# RS1xxxx register map
Vendor: Silicon Lab Inc.; Series: ARMCM4; File version: 1.2
CPU: CM4 r1p0, little endian, MPU, FPU, 6 interrupt priority bits
Registers are 32-bit, read-write, reset 0x0 unless marked. A register's access mark holds for its fields unless they carry their own. Offsets are from the block's base; [hi:lo] are bit positions; 'fields as' and 'values as' point back to an identical list.

## I2C0 — Inter Integrated Circuit(I2C) is programmable control bus that provides support for the communications link between integrated circuits in a system
Base 0x44010000
Same registers: ULP_I2C 0x24040000, I2C1 0x47040000
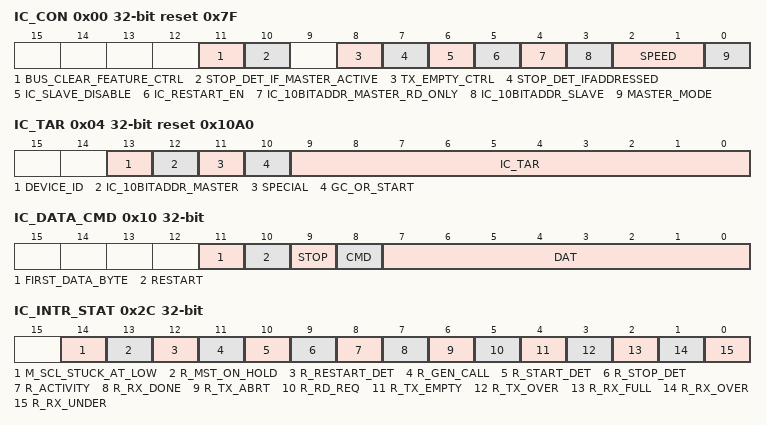
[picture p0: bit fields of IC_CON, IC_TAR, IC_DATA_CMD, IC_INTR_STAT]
0x00 IC_CON reset 0x7F — This register can be written only when the i2c is disabled, which corresponds to IC_ENABLE[0] being set to 0. Writes at other times have no effect.
  [11] BUS_CLEAR_FEATURE_CTRL — In Master mode.
    0=Disable (Bus Clear Feature is disabled); 1=Enable (Bus Clear Feature is enabled)
  [10] STOP_DET_IF_MASTER_ACTIVE — In Master mode.
    0=Disable (Issues the STOP_DET irrespective of whether the master is active.); 1=Enable (Issues the STOP_DET interrupt only when the master is active)
  [8] TX_EMPTY_CTRL — This bit controls the generation of the TX EMPTY interrupt, as described in the IC RAW INTR STAT register.
  [7] STOP_DET_IFADDRESSED — The STOP DETECTION interrupt is generated only when the transmitted address matches the slave address of SAR
    0=Disable (Issues the STOP DETECTION irrespective of whether it is addressed or not.); 1=Enable (issues the STOP DETECTION interrupt only when it is addressed.)
  [6] IC_SLAVE_DISABLE — This bit controls whether I2C has its slave disabled
    0=Disable (slave is enabled); 1=Enable (slave is disabled)
  [5] IC_RESTART_EN — Determines whether RESTART conditions may be sent when acting as a master
    0=Disabled; 1=Enabled
  [4] IC_10BITADDR_MASTER_RD_ONLY ro — the function of this bit is handled by bit 12 of IC_TAR register, and becomes a read-only copy called IC_10BITADDR_MASTER_rd_only
    0=Disable (7-bit addressing); 1=Enable (10-bit addressing)
  [3] IC_10BITADDR_SLAVE — When acting as a slave, this bit controls whether the I2C responds to 7- or 10-bit addresses.
    0=Disable (7-bit addressing. The DW_apb_i2c ignores transactions that involve 10-bit addressing; for 7-bit addressing, only the lower 7 bits of the IC_SAR register are compared); 1=Enable (10-bit addressing. The DW_apb_i2c responds to only 10-bit addressing transfers that match the full 10 bits of the IC_SAR register.)
  [2:1] SPEED — These bits control at which speed the I2C operates. Hardware protects against illegal values being programmed by software.
    1=standard mode (0 to 100 kbit/s); 2=fast mode (less than or equal 400 kbit/s); 3=high speed mode (less than or equal 3.4 Mbit/s)
  [0] MASTER_MODE — This bit controls whether the I2C master is enabled.
    0=Disable (master disabled); 1=Enable (master enabled)
0x04 IC_TAR reset 0x10A0 — I2C Target Address Register
  [13] DEVICE_ID — If bit 11 (SPECIAL) is set to 1, then this bit indicates whether a Device-ID of a particular slave mentioned in IC_TAR[6:0] is to be performed by the I2C Master
    0=Disable (Device-ID is not performed and checks ic_tar[10] to perform either general call or START byte command.); 1=Enable (: Device-ID transfer is performed and bytes based on the number of read commands in the Tx-FIFO are received from the targeted slave and put in the Rx-FIFO.)
  [12] IC_10BITADDR_MASTER — This bit controls whether the i2c starts its transfers in 7-or 10-bit addressing mode when acting as a master
    0=Disable (7-bit addressing); 1=Enable (10-bit addressing)
  [11] SPECIAL — This bit indicates whether software performs a General Call or START BYTE command
    0=Disable (ignore bit 10 GC_OR_START and use IC_TAR normally); 1=Enable (perform special I2C command as specified in GC_OR_START bit)
  [10] GC_OR_START — If bit 11 (SPECIAL) is set to 1, then this bit indicates whether a General Call or START byte command is to be performed by the DW_apb_i2c
    0=Disable (General Call Address); 1=Enable (START BYTE)
  [9:0] IC_TAR — This is the target address for any master transaction
0x08 IC_SAR reset 0x55 — I2C Slave Address Register
  [9:0] IC_SAR — The IC_SAR holds the slave address when the I2C is operating as a slave. For 7-bit addressing, only IC_SAR[6:0] is used.
0x0C IC_HS_MADDR reset 0x1 — I2C High Speed Master Mode Code Address Register
  [2:0] IC_HS_MAR — This bit field holds the value of the I2C HS mode master code
0x10 IC_DATA_CMD — I2C Rx/Tx Data Buffer and Command Register
  [11] FIRST_DATA_BYTE ro — Indicates the first data byte received after the address phase for receive transfer in Master receiver or Slave receiver mode
    0=Disable (If IC_RESTART_EN is 1, a RESTART is issued only if the transfer direction is changing from the previous command); 1=Enable (If IC_RESTART_EN is 1, a RESTART is issued before the data is sent/received)
  [10] RESTART wo — This bit controls whether a RESTART is issued before the byte is sent or received
    values as FIRST_DATA_BYTE
  [9] STOP wo — This bit controls whether a STOP is issued after the byte is sent or received
    0=Disable (STOP is not issued after this byte, regardless of whether or not the Tx FIFO is empty); 1=Enable (STOP is issued after this byte, regardless of whether or not the Tx FIFO is empty)
  [8] CMD wo — This bit controls whether a read or a write is performed
    0=Disable (write); 1=Enable (Read)
  [7:0] DAT — This register contains the data to be transmitted or received on the I2C bus
0x14 IC_SS_SCL_HCNT reset 0x1F4 — Standard Speed I2C Clock SCL High Count Register
  [15:0] IC_SS_SCL_HCNT — This register must be set before any I2C bus transaction can take place to ensure proper I/O timing
0x18 IC_SS_SCL_LCNT reset 0x24C — Standard Speed I2C Clock SCL Low Count Register
  [15:0] IC_SS_SCL_LCNT — This register must be set before any I2C bus transaction can take place to ensure proper I/O timing
0x1C IC_FS_SCL_HCNT reset 0x4B — Fast Speed I2C Clock SCL High Count Register
  [15:0] IC_FS_SCL_HCNT — This register must be set before any I2C bus transaction can take place to ensure proper I/O timing
0x20 IC_FS_SCL_LCNT reset 0xA3 — Fast Speed I2C Clock SCL Low Count Register
  [15:0] IC_FS_SCL_LCNT — This register must be set before any I2C bus transaction can take place to ensure proper I/O timing
0x24 IC_HS_SCL_HCNT reset 0xF — High Speed I2C Clock SCL High Count Register
  [15:0] IC_HS_SCL_HCNT — This register must be set before any I2C bus transaction can take place to ensure proper I/O timing
0x28 IC_HS_SCL_LCNT reset 0x28 — High Speed I2C Clock SCL Low Count Register
  [15:0] IC_HS_SCL_LCNT — This register must be set before any I2C bus transaction can take place to ensure proper I/O timing
0x2C IC_INTR_STAT ro — I2C Interrupt Status Register
  [14] M_SCL_STUCK_AT_LOW — Indicates whether the SCL Line is stuck at low for the IC_SCL_STUCK_LOW_TIMOUT number of ic_clk periods
  [13] R_MST_ON_HOLD — Indicates whether a master is holding the bus and the Tx FIFO is empty.
  [12] R_RESTART_DET — Indicates whether a RESTART condition has occurred on the I2C interface when DW_apb_i2c is operating in slave mode and the slave is the addressed slave
  [11] R_GEN_CALL — Set only when a General Call address is received and it is acknowledged
  [10] R_START_DET — Indicates whether a START or RESTART condition has occurred on the I2C interface regardless of whether DW_apb_i2c is operating in slave or master mode.
  [9] R_STOP_DET — Indicates whether a STOP condition has occurred on the I2C interface regardless of whether DW_apb_i2c is operating in slave or master mode.
  [8] R_ACTIVITY — This bit captures DW_apb_i2c activity and stays set until it is cleared
  [7] R_RX_DONE — When the DW_apb_i2c is acting as a slave-transmitter, this bit is set to 1 if the master does not acknowledge a transmitted byte
  [6] R_TX_ABRT — This bit indicates if DW_apb_i2c, as an I2C transmitter, is unable to complete the intended actions on the contents of the transmit FIFO
  [5] R_RD_REQ — This bit is set to 1 when DW_apb_i2c is acting as a slave and another I2C master is attempting to read data from DW_apb_i2c.
  [4] R_TX_EMPTY — This bit is set to 1 when the transmit buffer is at or below the threshold value set in the IC_TX_TL register.
  [3] R_TX_OVER — Set during transmit if the transmit buffer is filled to IC_TX_BUFFER_DEPTH and the processor attempts to issue another I2C command by writing to the IC_DATA_CMD register.
  [2] R_RX_FULL — Set when the receive buffer reaches or goes above the RX_TL threshold in the IC_RX_TL register.
  [1] R_RX_OVER — Set if the receive buffer is completely filled to IC_RX_BUFFER_DEPTH and an additional byte is received from an external I2C device
  [0] R_RX_UNDER — Set if the processor attempts to read the receive buffer when it is empty by reading from the IC_DATA_CMD register
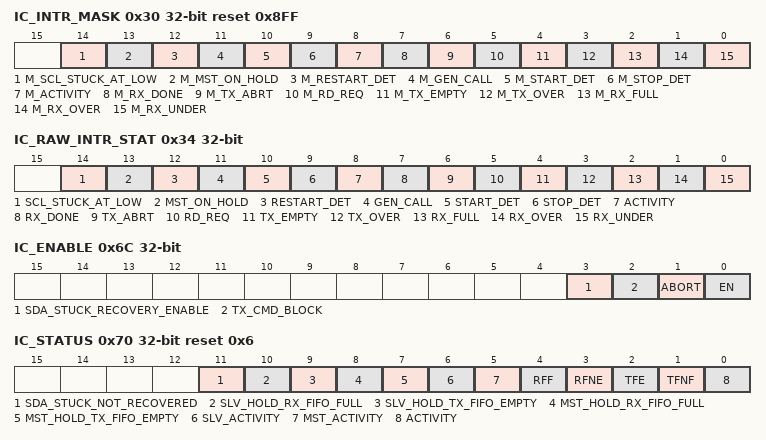
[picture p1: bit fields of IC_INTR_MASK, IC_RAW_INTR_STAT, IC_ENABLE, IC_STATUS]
0x30 IC_INTR_MASK reset 0x8FF — I2C Interrupt Mask Register
  [14] M_SCL_STUCK_AT_LOW — Indicates whether the SCL Line is stuck at low for the IC_SCL_STUCK_LOW_TIMOUT number of ic_clk periods
  [13] M_MST_ON_HOLD — Indicates whether a master is holding the bus and the Tx FIFO is empty.
  [12] M_RESTART_DET — Indicates whether a RESTART condition has occurred on the I2C interface when DW_apb_i2c is operating in slave mode and the slave is the addressed slave
  [11] M_GEN_CALL — This bit mask their corresponding interrupt status bits in the IC_INTR_STAT register.
  [10] M_START_DET — This bit mask their corresponding interrupt status bits in the IC_INTR_STAT register.
  [9] M_STOP_DET — This bit mask their corresponding interrupt status bits in the IC_INTR_STAT register.
  [8] M_ACTIVITY — This bit mask their corresponding interrupt status bits in the IC_INTR_STAT register.
  [7] M_RX_DONE — This bit mask their corresponding interrupt status bits in the IC_INTR_STAT register.
  [6] M_TX_ABRT — This bit mask their corresponding interrupt status bits in the IC_INTR_STAT register.
  [5] M_RD_REQ — This bit mask their corresponding interrupt status bits in the IC_INTR_STAT register.
  [4] M_TX_EMPTY — This bit mask their corresponding interrupt status bits in the IC_INTR_STAT register.
  [3] M_TX_OVER — This bit mask their corresponding interrupt status bits in the IC_INTR_STAT register
  [2] M_RX_FULL — This bit mask their corresponding interrupt status bits in the IC_INTR_STAT register.
  [1] M_RX_OVER — This bit mask their corresponding interrupt status bits in the IC_INTR_STAT register.
  [0] M_RX_UNDER — This bit mask their corresponding interrupt status bits in the IC_INTR_STAT register.
0x34 IC_RAW_INTR_STAT ro — I2C Raw Interrupt Status Register
  [14] SCL_STUCK_AT_LOW — Indicates whether the SCL Line is stuck at low for the IC_SCL_STUCK_LOW_TIMOUT number of ic_clk periods
  [13] MST_ON_HOLD — Indicates whether a master is holding the bus and the Tx FIFO is empty.
  [12] RESTART_DET — Indicates whether a RESTART condition has occurred on the I2C interface when DW_apb_i2c is operating in slave mode and the slave is the addressed slave
  [11] GEN_CALL — Set only when a General Call address is received and it is acknowledged
  [10] START_DET — Indicates whether a START or RESTART condition has occurred on the I2C interface regardless of whether DW_apb_i2c is operating in slave or master mode.
  [9] STOP_DET — Indicates whether a STOP condition has occurred on the I2C interface regardless of whether DW_apb_i2c is operating in slave or master mode.
  [8] ACTIVITY — This bit captures DW_apb_i2c activity and stays set until it is cleared
  [7] RX_DONE — When the DW_apb_i2c is acting as a slave-transmitter, this bit is set to 1 if the master does not acknowledge a transmitted byte
  [6] TX_ABRT — This bit indicates if DW_apb_i2c, as an I2C transmitter, is unable to complete the intended actions on the contents of the transmit FIFO
  [5] RD_REQ — This bit is set to 1 when DW_apb_i2c is acting as a slave and another I2C master is attempting to read data from DW_apb_i2c.
  [4] TX_EMPTY — This bit is set to 1 when the transmit buffer is at or below the threshold value set in the IC_TX_TL register.
  [3] TX_OVER — Set during transmit if the transmit buffer is filled to IC_TX_BUFFER_DEPTH and the processor attempts to issue another I2C command by writing to the IC_DATA_CMD register.
  [2] RX_FULL — Set when the receive buffer reaches or goes above the RX_TL threshold in the IC_RX_TL register.
  [1] RX_OVER — Set if the receive buffer is completely filled to IC_RX_BUFFER_DEPTH and an additional byte is received from an external I2C device
  [0] RX_UNDER — Set if the processor attempts to read the receive buffer when it is empty by reading from the IC_DATA_CMD register
0x38 IC_RX_TL reset 0x8 — I2C Receive FIFO Threshold Register
  [7:0] RX_TL — Receive FIFO Threshold Level
0x3C IC_TX_TL reset 0x8 — I2C Transmit FIFO Threshold Register
  [7:0] TX_TL — Transmit FIFO Threshold Level
0x40 IC_CLR_INTR ro — Clear Combined and Individual Interrupt Register
  [0] CLR_INTR — Read this register to clear the combined interrupt, all individual interrupts, and the IC_TXABRT_SOURCE register
0x44 IC_CLR_RX_UNDER ro — Clear RX_UNDER Interrupt Register
  [0] CLR_RX_UNDER — Read this register to clear the RX_UNDER interrupt (bit 0) of the IC_RAW_INTR_STAT register.
0x48 IC_CLR_RX_OVER ro — Clear RX_OVER Interrupt Register
  [0] CLR_RX_OVER — Read this register to clear the RX_OVER interrupt (bit 1) of the IC_RAW_INTR_STAT register
0x4C IC_CLR_TX_OVER ro — Clear TX_OVER Interrupt Register
  [0] CLR_TX_OVER — Read this register to clear the TX_OVER interrupt (bit 3) of the IC_RAW_INTR_STAT register.
0x50 IC_CLR_RD_REQ ro — Clear RD_REQ Interrupt Register
  [0] CLR_RD_REQ — Read this register to clear the RD_REQ interrupt (bit 5) of the IC_RAW_INTR_STAT register.
0x54 IC_CLR_TX_ABRT ro — Clear TX_ABRT Interrupt Register
  [0] CLR_TX_ABRT — Read this register to clear the TX_ABRT interrupt (bit 6) of the C_RAW_INTR_STAT register, and the IC_TX_ABRT_SOURCE register
0x58 IC_CLR_RX_DONE ro — Clear RX_DONE Interrupt Register
  [0] CLR_RX_DONE — Read this register to clear the RX_DONE interrupt (bit 7) of the IC_RAW_INTR_STAT register
0x5C IC_CLR_ACTIVITY ro — Clear ACTIVITY Interrupt Register
  [0] CLR_ACTIVITY — Reading this register clears the ACTIVITY interrupt if the I2C is not active any more
0x60 IC_CLR_STOP_DET ro — Clear STOP_DET Interrupt Register
  [0] CLR_STOP_DET — Read this register to clear the STOP_DET interrupt (bit 9) of the IC_RAW_INTR_STAT register.
0x64 IC_CLR_START_DET ro — Clear START_DET Interrupt Register
  [0] CLR_START_DET — Read this register to clear the START_DET interrupt (bit 10) of the IC_RAW_INTR_STAT register
0x68 IC_CLR_GEN_CALL ro — Clear GEN_CALL Interrupt Register
  [0] CLR_GEN_CALL — Read this register to clear the GEN_CALL interrupt (bit 11) of IC_RAW_INTR_STAT register
0x6C IC_ENABLE (reset mask 0x1) — Clear GEN_CALL Interrupt Register
  [3] SDA_STUCK_RECOVERY_ENABLE
  [2] TX_CMD_BLOCK
    0=Disable (The transmission of data starts on I2C bus automatically, as soon as the first data is available in the Tx FIFO); 1=Enable (Blocks the transmission of data on I2C bus even if Tx FIFO has data to transmit)
  [1] ABORT — When set, the controller initiates the transfer abort
    0=Disable (ABORT not initiated or ABORT done); 1=Enable (ABORT operation in progress)
  [0] EN — Controls whether the DW_apb_i2c is enabled
    0=Disables DW_apb_i2c (TX and RX FIFOs are held in an erased state); 1=Enables DW_apb_i2c
0x70 IC_STATUS ro reset 0x6 (reset mask 0xF) — I2C Status Register
  [11] SDA_STUCK_NOT_RECOVERED — This bit indicates that an SDA stuck at low is not recovered after the recovery mechanism.
  [10] SLV_HOLD_RX_FIFO_FULL — This bit indicates the BUS Hold in Slave mode due to the Rx FIFO being Full and an additional byte being received.
  [9] SLV_HOLD_TX_FIFO_EMPTY — This bit indicates the BUS Hold in Slave mode for the Read request when the Tx FIFO is empty.
  [8] MST_HOLD_RX_FIFO_FULL — This bit indicates the BUS Hold in Master mode due to Rx FIFO is Full and additional byte has been received.
  [7] MST_HOLD_TX_FIFO_EMPTY — The I2C master stalls the write transfer when Tx FIFO is empty, and the the last byte does not have the Stop bit set.
  [6] SLV_ACTIVITY — Slave FSM Activity Status
    0=Disable (Slave FSM is in IDLE state so the Slave part of DW_apb_i2c is not Active); 1=Enable (Slave FSM is not in IDLE state so the Slave part of DW_apb_i2c is Active)
  [5] MST_ACTIVITY — Master FSM Activity Status
    0=Disable (Master FSM is in IDLE state so the Master part of DW_apb_i2c is not Active); 1=Enable (Master FSM is not in IDLE state so the Master part of DW_apb_i2c is Active)
  [4] RFF — Receive FIFO Completely Full
    0=Disable (Receive FIFO is not full); 1=Enable (Receive FIFO is full)
  [3] RFNE — Receive FIFO Not Empty
    0=Disable (Receive FIFO is not empty); 1=Enable (Receive FIFO is not empty)
  [2] TFE — Transmit FIFO Completely Empty
    0=Disable (Transmit FIFO is not empty); 1=Enable (Transmit FIFO is empty)
  [1] TFNF — Transmit FIFO Not Full
    0=Disable (Transmit FIFO is full); 1=Enable (Transmit FIFO is not full)
  [0] ACTIVITY — I2C Activity Status
0x74 IC_TXFLR ro — I2C Transmit FIFO Level Register
  [3:0] TXFLR — Contains the number of valid data entries in the transmit FIFO.
0x78 IC_RXFLR ro — I2C Receive FIFO Level Register
  [3:0] RXFLR — Receive FIFO Level. Contains the number of valid data entries in the receive FIFO
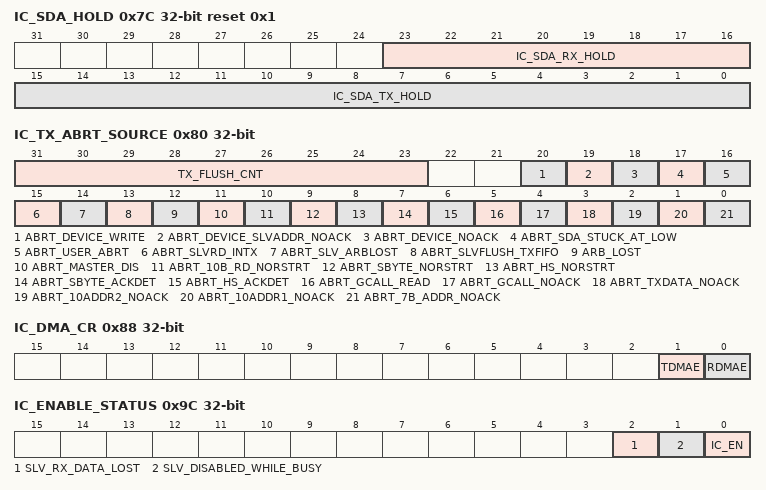
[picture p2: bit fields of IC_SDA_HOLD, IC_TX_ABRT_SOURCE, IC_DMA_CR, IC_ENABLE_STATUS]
0x7C IC_SDA_HOLD reset 0x1 (reset mask 0xF) — I2C SDA Hold Time Length Register
  [23:16] IC_SDA_RX_HOLD — Sets the required SDA hold time in units of ic_clk period,when I2C acts as a receiver.
  [15:0] IC_SDA_TX_HOLD — Sets the required SDA hold time in units of ic_clk period,when I2C acts as a transmitter.
0x80 IC_TX_ABRT_SOURCE ro (reset mask 0xFFFF) — I2C Transmit Abort Source Register
  [31:23] TX_FLUSH_CNT — This field indicates the number of Tx FIFO data commands that are flushed due to TX_ABRT interrupt
  [20] ABRT_DEVICE_WRITE — Master is initiating the DEVICE_ID transfer and the Tx- FIFO consists of write commands.
  [19] ABRT_DEVICE_SLVADDR_NOACK — Master is initiating the DEVICE_ID transfer and the slave address sent was not acknowledged by any slave
  [18] ABRT_DEVICE_NOACK — Master initiates the DEVICE_ID transfer and the device ID sent is not acknowledged by any slave
  [17] ABRT_SDA_STUCK_AT_LOW — Master detects the SDA is Stuck at low for the IC_SDA_STUCK_AT_LOW_TIMEOUT value of ic_clks
  [16] ABRT_USER_ABRT — This is a master-mode-only bit. Master has detected the transfer abort (IC_ENABLE[1]).
  [15] ABRT_SLVRD_INTX — 1: When the processor side responds to a slave mode request for data to be transmitted to a remote master and user writes a 1 in CMD (bit 8) of IC_DATA_CMD register
  [14] ABRT_SLV_ARBLOST — 1: Slave lost the bus while transmitting data to a remote master. IC_TX_ABRT_SOURCE[12] is set at the same time
  [13] ABRT_SLVFLUSH_TXFIFO — 1: Slave has received a read command and some data exists in the TX FIFO so the slave issues a TX_ABRT interrupt to flush old data in TX FIFO
  [12] ARB_LOST — 1: Master has lost arbitration, or if IC_TX_ABRT_SOURCE[14] is also set, then the slave transmitter has lost arbitration
  [11] ABRT_MASTER_DIS — 1: User tries to initiate a Master operation with the Master mode disabled
  [10] ABRT_10B_RD_NORSTRT — 1: The restart is disabled (IC_RESTART_EN bit (IC_CON[5]) = 0) and the master sends a read command in 10-bit addressing mode
  [9] ABRT_SBYTE_NORSTRT — 1: The restart is disabled (IC_RESTART_EN bit (IC_CON[5]) = 0) and the user is trying to send a START Byte
  [8] ABRT_HS_NORSTRT — 1: The restart is disabled (IC_RESTART_EN bit (IC_CON[5]) = 0) and the user is trying to use the master to transfer data in High Speed mode
  [7] ABRT_SBYTE_ACKDET — 1: Master has sent a START Byte and the START Byte was acknowledged (wrong behavior)
  [6] ABRT_HS_ACKDET — 1: Master is in High Speed mode and the High Speed Master code was acknowledged
  [5] ABRT_GCALL_READ — 1: DW_apb_i2c in master mode sent a General Call but the user programmed the byte following the General Call to be a read from the bus (IC_DATA_CMD[9] is set to 1)
  [4] ABRT_GCALL_NOACK — 1: DW_apb_i2c in master mode sent a General Call and no slave on the bus acknowledged the General Call
  [3] ABRT_TXDATA_NOACK — 1: This is a master-mode only bit. Master has received an acknowledgement for the address, but when it sent data byte(s) following the address, it did not receive an acknowledge from the remote slave(s)
  [2] ABRT_10ADDR2_NOACK — 1: Master is in 10-bit address mode and the second address byte of the 10-bit address was not acknowledged by any slave
  [1] ABRT_10ADDR1_NOACK — 1: Master is in 10-bit address mode and the first 10-bit address byte was not acknowledged by any slave
  [0] ABRT_7B_ADDR_NOACK — 1: Master is in 7-bit addressing mode and the address sent was not acknowledged by any slave
0x84 IC_SLV_DATA_NACK_ONLY — Generate Slave Data NACK Register
  [0] NACK — Generate NACK. This NACK generation only occurs when DW_apb_i2c is a slave receiver.
0x88 IC_DMA_CR — DMA Control Register
  [1] TDMAE — Transmit DMA Enable.This bit enables/disables the transmit FIFO DMA channel
    0=Disable (Transmit DMA disabled); 1=Enable (Transmit DMA enabled)
  [0] RDMAE — Receive DMA Enable
    0=Disable (Receive DMA disabled); 1=Enable (Receive DMA enabled)
0x8C IC_DMA_TDLR — DMA Transmit Data Level Register
  [3:0] DMATDL — This bit field controls the level at which a DMA request is made by the transmit logic
0x90 IC_DMA_RDLR (reset mask 0x7) — I2C Receive Data Level Register
  [3:0] DMARDL — This bit field controls the level at which a DMA request is made by the receive logic
0x94 IC_SDA_SETUP — I2C SDA Setup Register
  [7:0] SDA_SETUP — This register controls the amount of time delay (in terms of number of ic_clk clock periods)
0x98 IC_ACK_GENERAL_CALL reset 0x1 — I2C ACK General Call Register
  [0] ACK_GEN_CALL — ACK General Call
    0=Disable (DW_apb_i2c does not generate General Call interrupts); 1=Enable (DW_apb_i2c responds with a ACK (by asserting ic_data_oe) when it receives a General Call.)
0x9C IC_ENABLE_STATUS ro — I2C Enable Status Register
  [2] SLV_RX_DATA_LOST — Slave Received Data Lost
    0=Disable (DW_apb_i2c is deemed to have been actively engaged in an aborted I2C transfer (with matching address) and the data phase of the I2C transfer has been entered, even though a data byte has been responded with a NACK); 1=Enable (DW_apb_i2c is deemed to have been disabled without being actively involved in the data phase of a Slave-Receiver transfer)
  [1] SLV_DISABLED_WHILE_BUSY — This bit indicates if a potential or active Slave operation has been aborted due to the setting of the IC_ENABLE register from 1 to 0
    0=Disable (DW_apb_i2c is deemed to have been disabled when there is master activity, or when the I2C bus is idle.); 1=Enable (DW_apb_i2c is deemed to have forced a NACK during any part of an I2C transfer)
  [0] IC_EN — This bit always reflects the value driven on the output port ic_en.
    0=Disable (DW_apb_i2c is deemed completely inactive); 1=Enable (DW_apb_i2c is deemed to be in an enabled state)
0xA0 IC_FS_SPKLEN reset 0x6 (alternate view of IC_UFM_SPKLEN) — I2C SS and FS Spike Suppression Limit Register
  [7:0] IC_FS_SPKLEN — This register sets the duration, measured in ic_clk cycles, of the longest spike in the SCL or SDA lines that are filtered out by the spike suppression logic
0xA4 IC_HS_SPKLEN reset 0x2 — I2C HS Spike Suppression Limit Register
  [7:0] IC_HS_SPKLEN — This register sets the duration, measured in ic_clk cycles, of the longest spike in the SCL or SDA lines that are filtered out by the spike suppression logic
0xA8 IC_CLR_RESTART_DET ro — Clear RESTART_DET Interrupt Register
  [0] CLR_RESTART_DET — Read this register to clear the RESTART_DET interrupt (bit 12) of the IC_RAW_INTR_STAT registe
0xAC IC_SCL_STUCK_AT_LOW_TIMEOUT reset 0xFFFFFFFF — I2C SCL Stuck at Low Timeout
  [31:0] IC_SCL_STUCK_LOW_TIMEOUT — Generates the interrupt to indicate SCL stuck at low if it detects the SCL stuck at low for the IC_SCL_STUCK_LOW_TIMEOUT in units of ic_clk period
0xB0 IC_SDA_STUCK_AT_LOW_TIMEOUT reset 0xFFFFFFFF — I2C SDA Stuck at Low Timeout
  [31:0] IC_SDA_STUCK_LOW_TIMEOUT — Initiates the recovery of SDA line , if it detects the SDA stuck at low for the IC_SDA_STUCK_LOW_TIMEOUT in units of ic_clk period.
0xB4 IC_CLR_SCL_STUCK_DET ro — Clear SCL Stuck at Low Detect Interrupt Register
  [0] CLR_SCL_STUCK — Read this register to clear the SCL_STUCK_DET interrupt
0xB8 IC_DEVICE_ID ro reset 0x1 — I2C Device ID
  [0] DEVICE_ID — Contains the Device-ID of the component assigned through the configuration parameter
0xBC IC_SMBUS_CLOCK_LOW_SEXT reset 0xFFFFFFFF — SMBUS Slave Clock Extend Timeout Register
  [31:0] SMBUS_CLK_LOW_SEXT_TIMEOUT — The values in this register are in units of ic_clk period.
0xC0 IC_SMBUS_CLOCK_LOW_MEXT reset 0xFFFFFFFF — SMBUS Master extend clock Timeout Register
  [31:0] SMBUS_CLK_LOW_MEXT_TIMEOUT — The values in this register are in units of ic_clk period..
0xC4 IC_SMBUS_THIGH_MAX_IDLE_COUNT reset 0xFFFF — SMBus Thigh MAX Bus-Idle count Register
  [15:0] SMBUS_THIGH_MAX_BUS_IDLE_CNT — The values in this register are in units of ic_clk period.
0xC8 IC_SMBUS_INTR_STAT reset not defined — SMBUS Interrupt Status Register
0xCC IC_SMBUS_INTR_MASK reset not defined — Interrupt Mask Register
0xD0 IC_SMBUS_INTR_RAW_STATUS reset not defined — SMBUS Raw Interrupt Status Register
0xD4 IC_CLR_SMBUS_INTR reset not defined — Clear SMBUS Interrupt Register
0xD8 IC_OPTIONAL_SAR reset not defined — Optional Slave Address Register
0xDC IC_SMBUS_UDID_LSB reset 0xFFFFFFFF — SMBUS ARP UDID LSB Register
  [31:0] IC_SMBUS_ARP_UDID_LSB — This field is used to store the LSB 32 bit value of slave unique device identifier used in Address Resolution Protocol.
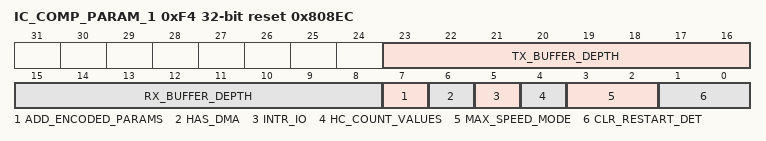
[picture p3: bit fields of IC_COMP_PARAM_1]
0xF4 IC_COMP_PARAM_1 ro reset 0x808EC — I2C HS Spike Suppression Limit Register
  [23:16] TX_BUFFER_DEPTH — Depth of Transmit buffer;the buffer is 8 bits wide;2 to 256
  [15:8] RX_BUFFER_DEPTH — Depth of receive buffer;the buffer is 8 bits wide;2 to 256
  [7] ADD_ENCODED_PARAMS — Add Encoded Parameters
  [6] HAS_DMA — DMA Handshake Interface signal
  [5] INTR_IO — Single Interrupt Output port
  [4] HC_COUNT_VALUES — Hard Code the count values
  [3:2] MAX_SPEED_MODE — Maximum Speed Mode
  [1:0] CLR_RESTART_DET — Read this register to clear the RESTART_DET interrupt (bit 12) of the IC_RAW_INTR_STAT register
0xF8 IC_COMP_VERSION ro — I2C Component Version Register
  [31:0] IC_COMP_VERSION — Signifies the component version
0xFC IC_COMP_TYPE ro — I2C Component Type Register
  [31:0] IC_COMP_TYPE — Design ware Component Type number = 0x44_57_01_40

## Notices in the file
Copyright (C) 2012 ARM Limited. All rights reserved.
Purpose: System Viewer Description (SVD) Example (Schema Version 1.1)
This is a description of a none-existent and incomplete device
for demonstration purposes only.
Redistribution and use in source and binary forms, with or without
modification, are permitted provided that the following conditions are met:
- Redistributions of source code must retain the above copyright
notice, this list of conditions and the following disclaimer.
- Redistributions in binary form must reproduce the above copyright
notice, this list of conditions and the following disclaimer in the
documentation and/or other materials provided with the distribution.
- Neither the name of ARM nor the names of its contributors may be used
to endorse or promote products derived from this software without
specific prior written permission.
THIS SOFTWARE IS PROVIDED BY THE COPYRIGHT HOLDERS AND CONTRIBUTORS "AS IS"
AND ANY EXPRESS OR IMPLIED WARRANTIES, INCLUDING, BUT NOT LIMITED TO, THE
IMPLIED WARRANTIES OF MERCHANTABILITY AND FITNESS FOR A PARTICULAR PURPOSE
ARE DISCLAIMED. IN NO EVENT SHALL COPYRIGHT HOLDERS AND CONTRIBUTORS BE
LIABLE FOR ANY DIRECT, INDIRECT, INCIDENTAL, SPECIAL, EXEMPLARY, OR
CONSEQUENTIAL DAMAGES (INCLUDING, BUT NOT LIMITED TO, PROCUREMENT OF
SUBSTITUTE GOODS OR SERVICES; LOSS OF USE, DATA, OR PROFITS; OR BUSINESS
INTERRUPTION) HOWEVER CAUSED AND ON ANY THEORY OF LIABILITY, WHETHER IN
CONTRACT, STRICT LIABILITY, OR TORT (INCLUDING NEGLIGENCE OR OTHERWISE)
ARISING IN ANY WAY OUT OF THE USE OF THIS SOFTWARE, EVEN IF ADVISED OF THE
POSSIBILITY OF SUCH DAMAGE.
